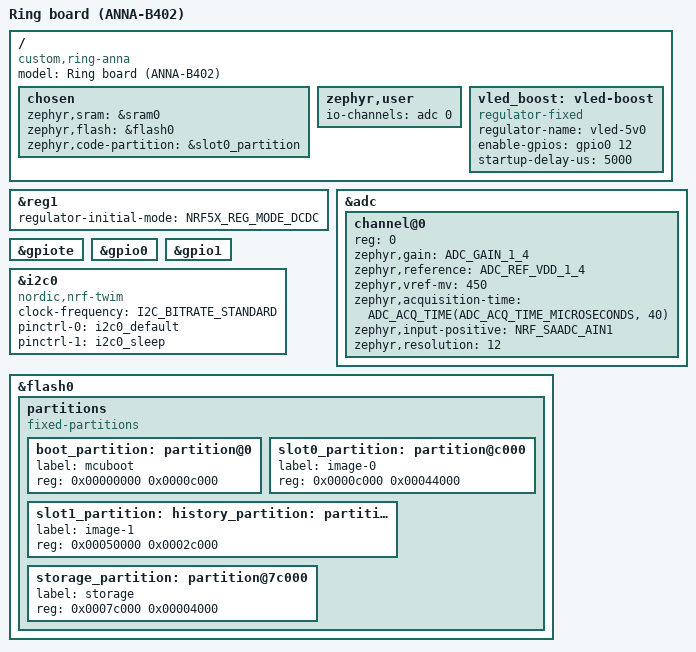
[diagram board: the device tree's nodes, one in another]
/dts-v1/;
#include <nordic/nrf52833_qiaa.dtsi>
#include "ring_anna-pinctrl.dtsi"
#include <zephyr/dt-bindings/adc/adc.h>
#include <zephyr/dt-bindings/adc/nrf-saadc.h>

/ {
	model = "Ring board (ANNA-B402)";
	compatible = "custom,ring-anna";

	chosen {
		zephyr,sram = &sram0;
		zephyr,flash = &flash0;
		zephyr,code-partition = &slot0_partition;
	};

	zephyr,user {
		io-channels = <&adc 0>;
	};

	/*
	 * TPS61240 boost (U1). BOOST_EN = U5.15 = GPIO_15 = P0.12.
	 * Its 5V output feeds MAXM86161 VLED (U3.5). Nothing on the
	 * board turns this on for us, so the firmware must.
	 */
	vled_boost: vled-boost {
		compatible = "regulator-fixed";
		regulator-name = "vled-5v0";
		enable-gpios = <&gpio0 12 GPIO_ACTIVE_HIGH>;
		startup-delay-us = <5000>;
	};
};

/*
 * ANNA-B402 carries the DC/DC inductors inside the module, so the SoC
 * regulator can run in buck mode instead of LDO.
 */
&reg1 {
	regulator-initial-mode = <NRF5X_REG_MODE_DCDC>;
};

/*
 * GSR front end. U7 (OPA2333) drives GSR_ADC into P0.03 = AIN1.
 * GSR_PWR (P0.11) powers the divider; leave it off when not measuring.
 *
 * The node is channel@0, not channel@1. The channel index is just a SAADC
 * channel slot and is independent of the analog input; the input is chosen
 * by zephyr,input-positive below.
 *
 * This used to be channel@1. The move is a hypothesis, not a confirmed fix,
 * and it is worth being honest about that: adc_nrfx_saadc.c rejects a
 * channel_id only when it is >= SAADC_CH_NUM, and accepts channel 1 with any
 * input exactly as it accepts channel 0. Nothing in the driver requires
 * index 0.
 *
 * The missing zephyr,vref-mv below -- already fixed -- on its own explains
 * every 0 mV reading this project has ever recorded, because the conversion
 * multiplied by a vref of zero. So the most likely outcome of the A/B in
 * gsr_ain_scan() is that ch0 and ch1 read the same, meaning the index was
 * never the fault.
 *
 * The move is harmless either way and has been made; the bench log decides.
 * See HANDOFF.md section 5, "Cause 2". Moved 2026-09-17.
 */
&adc {
	status = "okay";
	#address-cells = <1>;
	#size-cells = <0>;

	channel@0 {
		reg = <0>;
		zephyr,gain = "ADC_GAIN_1_4";
		zephyr,reference = "ADC_REF_VDD_1_4";
		/*
		 * MANDATORY for any reference other than ADC_REF_INTERNAL.
		 * ADC_DT_SPEC_GET defaults vref_mv to 0 when this property is
		 * absent, and adc_raw_to_millivolts_dt() computes
		 * raw * vref_mv -- so every conversion returns 0 mV however
		 * good the sample is. That read as "GSR is dead" for weeks.
		 *
		 * Reference here is VDD/4 with VDD = 1.8 V, so 450 mV. Gain
		 * 1/4 is inverted by the conversion, giving full scale 1.8 V.
		 */
		zephyr,vref-mv = <450>;
		zephyr,acquisition-time = <ADC_ACQ_TIME(ADC_ACQ_TIME_MICROSECONDS, 40)>;
		zephyr,input-positive = <NRF_SAADC_AIN1>;
		zephyr,resolution = <12>;
	};
};

&gpiote {
	status = "okay";
};

&gpio0 {
	status = "okay";
};

&gpio1 {
	status = "okay";
};

/* MAXM86161 (U3) and LSM6DSV (U4) share this bus at 1V8. */
&i2c0 {
	compatible = "nordic,nrf-twim";
	status = "okay";
	/* 100 kHz rather than 400 kHz: more timing margin while bringing
	 * the board up. The MAXM86161 and LSM6DSV both support 400 kHz.
	 */
	clock-frequency = <I2C_BITRATE_STANDARD>;
	pinctrl-0 = <&i2c0_default>;
	pinctrl-1 = <&i2c0_sleep>;
	pinctrl-names = "default", "sleep";
};

/*
 * nrf52833_qiaa.dtsi gives flash0 as one undivided 512 kB region with no
 * partitions node at all, so there was nowhere for the settings subsystem
 * to put BLE bonds. Split it.
 *
 * 16 kB of storage is four erase pages; settings_nvs caps its sector count
 * at what the partition actually holds, so this gives NVS four sectors --
 * ample for a single bond's keys and CCC state.
 *
 * Since v0.9.0 the bottom of flash is MCUboot, and over-the-air updates
 * need somewhere to land. Two full image slots do not fit: the image is
 * ~245 kB with the SMP server, and 2 x 245 + bootloader + bonds leaves
 * nothing for the history log. So the update is LZMA2-compressed
 * (MCUboot overwrite-only mode, SB_CONFIG_MCUBOOT_COMPRESSED_IMAGE_SUPPORT)
 * and lands in the history partition, which doubles as slot 1. An update
 * therefore costs the history -- the app syncs first, src/ota.c stops the
 * log writing for the duration, and history_init() formats the region
 * again on the next boot. See OTA.md.
 *
 * zephyr,code-partition above is what makes this binding rather than
 * decorative: with CONFIG_USE_DT_CODE_PARTITION the linker is told the
 * image ends at 0x50000, so an image that grew into the history log or
 * the bonds would fail to link instead of quietly eating them at run time.
 *
 * NVS does NOT recover from stale bytes at 0x7c000 by itself. nvs_init()
 * returns -EDEADLK when every sector looks closed, and only rebuilds the
 * region if CONFIG_NVS_INIT_BAD_MEMORY_REGION is set -- which prj.conf
 * does, with the reasoning. Erase the part before the first flash anyway;
 * see release/README.md.
 */
&flash0 {
	partitions {
		compatible = "fixed-partitions";
		#address-cells = <1>;
		#size-cells = <1>;

		/* MCUboot, overwrite-only, with the LZMA2 decompressor. */
		boot_partition: partition@0 {
			label = "mcuboot";
			reg = <0x00000000 0x0000c000>;
		};

		/*
		 * 272 kB for the running image, ~245 kB as of v0.9.0. It
		 * starts with MCUboot's 512-byte image header.
		 */
		slot0_partition: partition@c000 {
			label = "image-0";
			reg = <0x0000c000 0x00044000>;
		};

		/*
		 * On-ring history (src/history.c): one 4 kB header page and
		 * 43 pages of 32-byte records, ~19 days at a 5-minute epoch.
		 * Also MCUboot's secondary slot: a compressed update is staged
		 * here, so it must stay at least as big as the compressed
		 * image (~150 kB). Unmoved since v0.6, so a v0.8 ring keeps
		 * its log across the reflash that adds the bootloader.
		 *
		 * MCUboot only looks inside this slot when the trailer at its
		 * end says an upgrade is pending (boot_validated_swap_type()),
		 * so the log is never mistaken for, or erased as, a bad image
		 * in a normal boot.
		 */
		slot1_partition: history_partition: partition@50000 {
			label = "image-1";
			reg = <0x00050000 0x0002c000>;
		};

		storage_partition: partition@7c000 {
			label = "storage";
			reg = <0x0007c000 0x00004000>;
		};
	};
};
